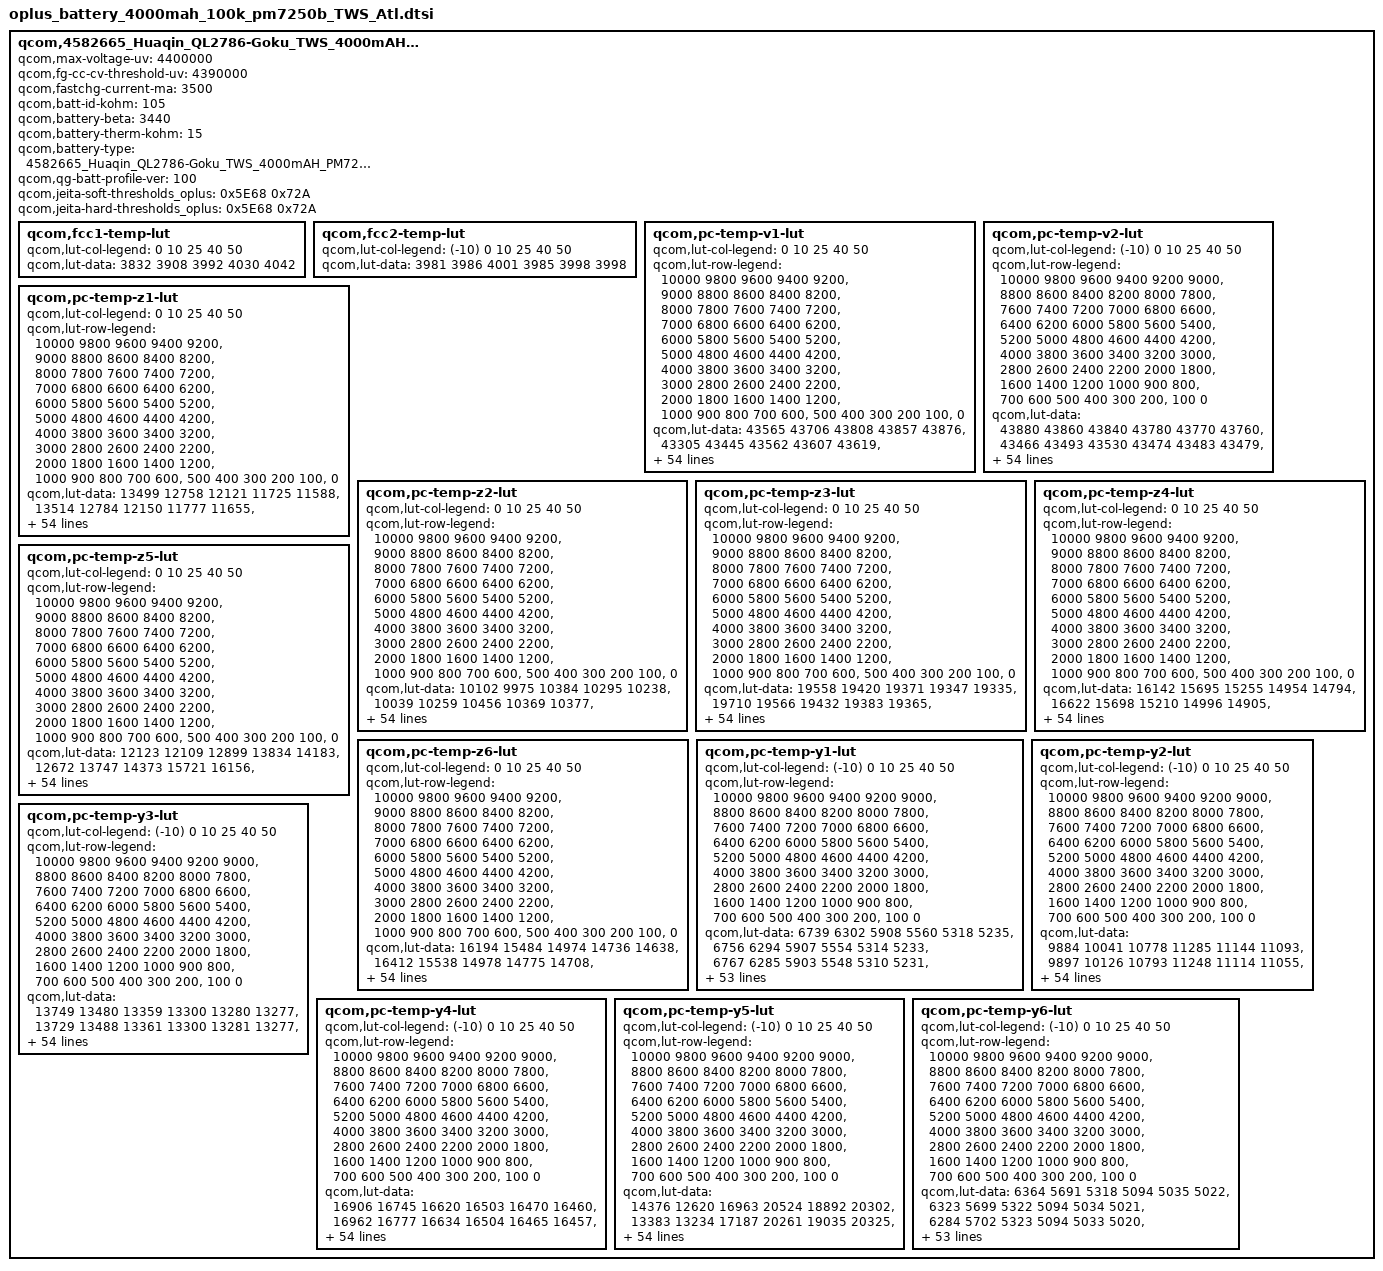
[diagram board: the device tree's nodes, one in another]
qcom,4582665_Huaqin_QL2786-Goku_TWS_4000mAH_PM7250B {
    /* 4582665_Huaqin_QL2786-Goku_TWS_4000mAH_PM7250B_averaged_MasterSlave_Dec05th2020 */
    qcom,max-voltage-uv = <4400000>;
    qcom,fg-cc-cv-threshold-uv = <4390000>;
    qcom,fastchg-current-ma = <3500>;
    qcom,batt-id-kohm = <105>;
    qcom,battery-beta = <3440>;
    qcom,battery-therm-kohm = <15>;
    qcom,battery-type = "4582665_Huaqin_QL2786-Goku_TWS_4000mAH_PM7250B_averaged_MasterSlave_Dec05th2020";
    qcom,qg-batt-profile-ver = <100>;
    qcom,jeita-soft-thresholds_oplus = <0x5E68 0x72A>;
    qcom,jeita-hard-thresholds_oplus = <0x5E68 0x72A>;

	qcom,fcc1-temp-lut {
		qcom,lut-col-legend = <0 10 25 40 50>;
		qcom,lut-data = <3832 3908 3992 4030 4042>;
	};

	qcom,fcc2-temp-lut {
		qcom,lut-col-legend = <(-10) 0 10 25 40 50>;
		qcom,lut-data = <3981 3986 4001 3985 3998 3998>;
	};

	qcom,pc-temp-v1-lut {
		qcom,lut-col-legend = <0 10 25 40 50>;
		qcom,lut-row-legend = <10000 9800 9600 9400 9200>,
			<9000 8800 8600 8400 8200>,
			<8000 7800 7600 7400 7200>,
			<7000 6800 6600 6400 6200>,
			<6000 5800 5600 5400 5200>,
			<5000 4800 4600 4400 4200>,
			<4000 3800 3600 3400 3200>,
			<3000 2800 2600 2400 2200>,
			<2000 1800 1600 1400 1200>,
			<1000 900 800 700 600>,
			<500 400 300 200 100>,
			<0>;
		qcom,lut-data = <43565 43706 43808 43857 43876>,
			<43305 43445 43562 43607 43619>,
			<43049 43194 43318 43370 43383>,
			<42801 42952 43076 43135 43151>,
			<42564 42714 42836 42900 42921>,
			<42335 42478 42597 42665 42691>,
			<42110 42246 42363 42432 42460>,
			<41889 42019 42130 42200 42227>,
			<41674 41796 41900 41969 41997>,
			<41467 41577 41672 41739 41766>,
			<41268 41365 41449 41511 41537>,
			<41068 41158 41232 41290 41316>,
			<40864 40956 41019 41074 41099>,
			<40660 40760 40813 40865 40890>,
			<40446 40565 40610 40660 40683>,
			<40218 40362 40416 40463 40484>,
			<40016 40158 40232 40276 40294>,
			<39867 39983 40057 40098 40114>,
			<39742 39842 39894 39927 39941>,
			<39615 39708 39745 39774 39784>,
			<39483 39562 39584 39612 39622>,
			<39352 39409 39395 39399 39419>,
			<39226 39238 39193 39148 39175>,
			<39102 39011 38990 38949 38974>,
			<38976 38785 38774 38800 38823>,
			<38837 38640 38616 38676 38696>,
			<38699 38535 38534 38572 38586>,
			<38583 38459 38472 38483 38490>,
			<38480 38406 38409 38399 38399>,
			<38399 38365 38346 38316 38309>,
			<38347 38325 38286 38241 38228>,
			<38308 38289 38229 38172 38156>,
			<38274 38253 38175 38110 38092>,
			<38244 38218 38126 38054 38032>,
			<38217 38184 38084 38006 37978>,
			<38189 38150 38043 37959 37926>,
			<38162 38118 38005 37911 37869>,
			<38126 38080 37965 37862 37810>,
			<38073 38019 37905 37798 37738>,
			<38000 37928 37812 37710 37647>,
			<37908 37825 37707 37608 37544>,
			<37779 37707 37597 37497 37431>,
			<37633 37570 37470 37370 37302>,
			<37466 37404 37305 37210 37142>,
			<37318 37255 37157 37067 37005>,
			<37221 37154 37058 36974 36917>,
			<37187 37126 37036 36948 36893>,
			<37160 37101 37015 36932 36875>,
			<37139 37076 36999 36913 36858>,
			<37088 37033 36953 36862 36800>,
			<36894 36833 36727 36614 36532>,
			<36449 36397 36292 36178 36096>,
			<35872 35829 35718 35603 35524>,
			<35091 35054 34934 34819 34744>,
			<33853 33843 33709 33604 33542>,
			<30000 30000 30000 30000 30000>;
	};

	qcom,pc-temp-v2-lut {
		qcom,lut-col-legend = <(-10) 0 10 25 40 50>;
		qcom,lut-row-legend = <10000 9800 9600 9400 9200 9000>,
			<8800 8600 8400 8200 8000 7800>,
			<7600 7400 7200 7000 6800 6600>,
			<6400 6200 6000 5800 5600 5400>,
			<5200 5000 4800 4600 4400 4200>,
			<4000 3800 3600 3400 3200 3000>,
			<2800 2600 2400 2200 2000 1800>,
			<1600 1400 1200 1000 900 800>,
			<700 600 500 400 300 200>,
			<100 0>;
		qcom,lut-data = <43880 43860 43840 43780 43770 43760>,
			<43466 43493 43530 43474 43483 43479>,
			<43095 43159 43238 43188 43211 43213>,
			<42774 42865 42967 42925 42957 42961>,
			<42493 42607 42717 42684 42719 42725>,
			<42241 42359 42472 42450 42486 42493>,
			<42025 42107 42227 42215 42252 42259>,
			<41823 41859 41986 41983 42019 42027>,
			<41588 41613 41753 41755 41790 41798>,
			<41304 41363 41525 41530 41564 41571>,
			<41066 41146 41305 41308 41341 41348>,
			<40936 40993 41093 41092 41122 41130>,
			<40827 40856 40888 40880 40907 40915>,
			<40617 40659 40688 40674 40702 40709>,
			<40183 40371 40491 40471 40501 40506>,
			<39783 40088 40295 40277 40309 40312>,
			<39559 39863 40102 40096 40124 40127>,
			<39383 39658 39906 39924 39946 39949>,
			<39207 39456 39697 39758 39776 39779>,
			<39032 39256 39471 39606 39618 39622>,
			<38867 39067 39254 39439 39446 39451>,
			<38706 38892 39056 39212 39227 39233>,
			<38555 38729 38874 38962 38994 39002>,
			<38431 38567 38714 38770 38808 38817>,
			<38328 38401 38572 38619 38651 38660>,
			<38240 38262 38447 38492 38517 38527>,
			<38166 38166 38339 38380 38405 38413>,
			<38103 38090 38240 38282 38307 38314>,
			<38043 38031 38142 38192 38218 38222>,
			<37986 37987 38041 38110 38136 38137>,
			<37932 37947 37960 38036 38062 38060>,
			<37880 37903 37899 37968 37996 37992>,
			<37829 37858 37849 37906 37934 37929>,
			<37774 37814 37809 37848 37868 37862>,
			<37716 37770 37778 37796 37801 37796>,
			<37656 37725 37744 37744 37729 37719>,
			<37593 37676 37706 37686 37644 37617>,
			<37526 37623 37664 37625 37553 37503>,
			<37458 37560 37609 37557 37468 37408>,
			<37385 37488 37538 37484 37389 37328>,
			<37314 37406 37453 37402 37305 37245>,
			<37246 37307 37351 37303 37213 37152>,
			<37180 37193 37230 37186 37109 37048>,
			<37114 37074 37084 37046 36970 36912>,
			<37043 36963 36945 36920 36853 36797>,
			<36953 36868 36844 36847 36802 36753>,
			<36896 36828 36812 36833 36787 36739>,
			<36838 36788 36777 36815 36775 36726>,
			<36767 36740 36729 36787 36747 36701>,
			<36657 36660 36645 36724 36675 36619>,
			<36453 36472 36451 36487 36383 36308>,
			<36087 36080 36024 36031 35902 35827>,
			<35521 35480 35418 35420 35276 35196>,
			<34685 34634 34576 34596 34414 34333>,
			<33254 33256 33244 33360 33133 33069>,
			<29010 28348 29127 28312 28764 29195>;
	};

	qcom,pc-temp-z1-lut {
		qcom,lut-col-legend = <0 10 25 40 50>;
		qcom,lut-row-legend = <10000 9800 9600 9400 9200>,
			<9000 8800 8600 8400 8200>,
			<8000 7800 7600 7400 7200>,
			<7000 6800 6600 6400 6200>,
			<6000 5800 5600 5400 5200>,
			<5000 4800 4600 4400 4200>,
			<4000 3800 3600 3400 3200>,
			<3000 2800 2600 2400 2200>,
			<2000 1800 1600 1400 1200>,
			<1000 900 800 700 600>,
			<500 400 300 200 100>,
			<0>;
		qcom,lut-data = <13499 12758 12121 11725 11588>,
			<13514 12784 12150 11777 11655>,
			<13530 12794 12165 11784 11666>,
			<13545 12798 12159 11783 11669>,
			<13539 12798 12145 11778 11667>,
			<13529 12790 12131 11773 11666>,
			<13525 12777 12117 11769 11665>,
			<13526 12759 12103 11765 11666>,
			<13523 12731 12093 11762 11666>,
			<13501 12710 12084 11760 11666>,
			<13451 12703 12079 11759 11665>,
			<13408 12698 12079 11758 11665>,
			<13382 12687 12079 11757 11665>,
			<13360 12658 12077 11757 11665>,
			<13335 12633 12073 11757 11665>,
			<13306 12627 12071 11757 11666>,
			<13285 12626 12073 11757 11666>,
			<13277 12627 12076 11758 11667>,
			<13273 12642 12077 11760 11668>,
			<13274 12657 12081 11761 11669>,
			<13279 12658 12084 11763 11670>,
			<13287 12656 12090 11764 11671>,
			<13305 12654 12096 11765 11671>,
			<13340 12654 12098 11767 11672>,
			<13363 12655 12100 11770 11674>,
			<13370 12660 12101 11773 11677>,
			<13375 12675 12104 11776 11680>,
			<13370 12686 12109 11781 11684>,
			<13334 12686 12113 11785 11688>,
			<13305 12684 12118 11789 11693>,
			<13312 12687 12123 11793 11697>,
			<13330 12691 12130 11798 11700>,
			<13344 12696 12138 11803 11703>,
			<13368 12706 12146 11808 11707>,
			<13391 12720 12156 11813 11711>,
			<13401 12728 12164 11817 11715>,
			<13417 12736 12167 11822 11718>,
			<13432 12743 12171 11827 11722>,
			<13445 12754 12175 11832 11725>,
			<13458 12768 12181 11838 11729>,
			<13465 12773 12188 11843 11732>,
			<13468 12774 12203 11849 11736>,
			<13468 12776 12217 11854 11740>,
			<13466 12809 12225 11859 11743>,
			<13490 12828 12234 11866 11746>,
			<13473 12803 12242 11870 11749>,
			<13475 12821 12242 11872 11749>,
			<13443 12819 12237 11872 11750>,
			<13471 12806 12258 11877 11754>,
			<13498 12822 12257 11881 11759>,
			<13491 12825 12258 11890 11764>,
			<13531 12848 12286 11901 11773>,
			<13524 12895 12299 11917 11785>,
			<13609 12944 12330 11937 11804>,
			<13609 12944 12330 11937 11804>,
			<13609 12944 12330 11937 11804>;
	};

	qcom,pc-temp-z2-lut {
		qcom,lut-col-legend = <0 10 25 40 50>;
		qcom,lut-row-legend = <10000 9800 9600 9400 9200>,
			<9000 8800 8600 8400 8200>,
			<8000 7800 7600 7400 7200>,
			<7000 6800 6600 6400 6200>,
			<6000 5800 5600 5400 5200>,
			<5000 4800 4600 4400 4200>,
			<4000 3800 3600 3400 3200>,
			<3000 2800 2600 2400 2200>,
			<2000 1800 1600 1400 1200>,
			<1000 900 800 700 600>,
			<500 400 300 200 100>,
			<0>;
		qcom,lut-data = <10102 9975 10384 10295 10238>,
			<10039 10259 10456 10369 10377>,
			<10108 10298 10494 10485 10499>,
			<10179 10278 10491 10538 10560>,
			<10231 10252 10453 10521 10526>,
			<10277 10220 10410 10491 10459>,
			<10288 10186 10369 10453 10409>,
			<10285 10170 10333 10395 10361>,
			<10279 10161 10322 10370 10333>,
			<10270 10155 10317 10376 10332>,
			<10252 10151 10315 10383 10335>,
			<10231 10148 10327 10379 10312>,
			<10203 10149 10349 10362 10240>,
			<10172 10166 10362 10338 10201>,
			<10141 10187 10373 10285 10216>,
			<10106 10200 10381 10239 10239>,
			<10087 10211 10389 10244 10249>,
			<10090 10226 10396 10272 10258>,
			<10096 10251 10405 10289 10269>,
			<10097 10278 10418 10295 10281>,
			<10091 10300 10438 10301 10299>,
			<10084 10321 10491 10392 10353>,
			<10085 10331 10552 10610 10469>,
			<10092 10334 10550 10677 10516>,
			<10102 10336 10496 10494 10444>,
			<10121 10337 10456 10319 10364>,
			<10145 10334 10446 10324 10374>,
			<10158 10333 10441 10367 10423>,
			<10166 10341 10450 10422 10458>,
			<10172 10356 10501 10517 10481>,
			<10178 10363 10536 10585 10495>,
			<10185 10366 10539 10564 10433>,
			<10191 10370 10539 10509 10276>,
			<10197 10377 10535 10481 10223>,
			<10203 10387 10527 10468 10237>,
			<10212 10393 10523 10462 10260>,
			<10223 10396 10531 10468 10298>,
			<10235 10400 10550 10483 10353>,
			<10250 10410 10574 10506 10402>,
			<10266 10427 10612 10556 10450>,
			<10283 10440 10638 10589 10482>,
			<10301 10449 10647 10571 10487>,
			<10323 10458 10650 10545 10483>,
			<10356 10466 10639 10539 10462>,
			<10602 10592 10681 10558 10458>,
			<10763 10646 10723 10555 10469>,
			<10809 10668 10692 10558 10479>,
			<10721 10734 10626 10555 10456>,
			<10399 10771 10636 10586 10507>,
			<10433 10790 10683 10668 10642>,
			<10705 10859 10833 10668 10440>,
			<12969 10853 10865 10479 10257>,
			<10137 10774 10818 10388 10218>,
			<10177 10615 10736 10345 10156>,
			<10177 10615 10736 10345 10156>,
			<10177 10615 10736 10345 10156>;
	};

	qcom,pc-temp-z3-lut {
		qcom,lut-col-legend = <0 10 25 40 50>;
		qcom,lut-row-legend = <10000 9800 9600 9400 9200>,
			<9000 8800 8600 8400 8200>,
			<8000 7800 7600 7400 7200>,
			<7000 6800 6600 6400 6200>,
			<6000 5800 5600 5400 5200>,
			<5000 4800 4600 4400 4200>,
			<4000 3800 3600 3400 3200>,
			<3000 2800 2600 2400 2200>,
			<2000 1800 1600 1400 1200>,
			<1000 900 800 700 600>,
			<500 400 300 200 100>,
			<0>;
		qcom,lut-data = <19558 19420 19371 19347 19335>,
			<19710 19566 19432 19383 19365>,
			<19804 19623 19474 19404 19385>,
			<19845 19653 19492 19415 19395>,
			<19821 19663 19503 19423 19398>,
			<19768 19662 19507 19428 19400>,
			<19731 19658 19503 19427 19401>,
			<19703 19653 19495 19424 19400>,
			<19685 19645 19489 19420 19400>,
			<19684 19636 19484 19415 19398>,
			<19685 19631 19478 19410 19394>,
			<19686 19626 19469 19403 19388>,
			<19687 19616 19460 19395 19379>,
			<19689 19591 19454 19388 19372>,
			<19697 19567 19450 19383 19369>,
			<19723 19559 19445 19379 19366>,
			<19741 19555 19437 19373 19362>,
			<19724 19548 19428 19366 19356>,
			<19690 19534 19422 19361 19351>,
			<19679 19522 19417 19358 19346>,
			<19681 19522 19415 19356 19343>,
			<19684 19527 19423 19361 19345>,
			<19686 19534 19437 19376 19354>,
			<19688 19545 19438 19380 19357>,
			<19692 19555 19432 19363 19341>,
			<19702 19556 19426 19346 19324>,
			<19714 19555 19418 19345 19325>,
			<19716 19553 19411 19344 19333>,
			<19713 19549 19411 19346 19344>,
			<19709 19545 19414 19364 19367>,
			<19703 19541 19419 19384 19385>,
			<19695 19537 19428 19390 19384>,
			<19686 19534 19438 19393 19378>,
			<19677 19533 19440 19393 19371>,
			<19667 19533 19437 19386 19363>,
			<19656 19532 19434 19377 19355>,
			<19643 19528 19428 19370 19350>,
			<19632 19523 19421 19365 19346>,
			<19622 19519 19417 19360 19342>,
			<19613 19515 19415 19357 19338>,
			<19606 19511 19413 19354 19336>,
			<19600 19505 19408 19353 19339>,
			<19593 19498 19403 19352 19344>,
			<19584 19488 19400 19352 19347>,
			<19520 19456 19390 19348 19344>,
			<19433 19441 19385 19343 19337>,
			<19383 19419 19376 19340 19328>,
			<19344 19404 19375 19333 19326>,
			<19263 19399 19352 19331 19313>,
			<19262 19400 19354 19324 19309>,
			<19262 19393 19337 19326 19340>,
			<19264 19377 19331 19343 19350>,
			<19305 19343 19331 19350 19350>,
			<19342 19339 19329 19350 19349>,
			<19342 19339 19329 19350 19349>,
			<19342 19339 19329 19350 19349>;
	};

	qcom,pc-temp-z4-lut {
		qcom,lut-col-legend = <0 10 25 40 50>;
		qcom,lut-row-legend = <10000 9800 9600 9400 9200>,
			<9000 8800 8600 8400 8200>,
			<8000 7800 7600 7400 7200>,
			<7000 6800 6600 6400 6200>,
			<6000 5800 5600 5400 5200>,
			<5000 4800 4600 4400 4200>,
			<4000 3800 3600 3400 3200>,
			<3000 2800 2600 2400 2200>,
			<2000 1800 1600 1400 1200>,
			<1000 900 800 700 600>,
			<500 400 300 200 100>,
			<0>;
		qcom,lut-data = <16142 15695 15255 14954 14794>,
			<16622 15698 15210 14996 14905>,
			<16368 15647 15155 14955 14885>,
			<16098 15444 15090 14911 14861>,
			<15922 15254 15007 14873 14836>,
			<15769 15144 14939 14837 14809>,
			<15640 15055 14893 14810 14786>,
			<15530 14987 14856 14787 14765>,
			<15434 14932 14822 14768 14748>,
			<15349 14888 14788 14750 14735>,
			<15273 14850 14766 14736 14725>,
			<15201 14819 14755 14728 14719>,
			<15127 14796 14747 14723 14715>,
			<15058 14778 14737 14717 14710>,
			<14996 14765 14726 14710 14703>,
			<14937 14759 14717 14702 14694>,
			<14893 14755 14711 14695 14687>,
			<14872 14750 14706 14689 14681>,
			<14857 14740 14700 14683 14675>,
			<14840 14730 14692 14674 14668>,
			<14818 14725 14688 14668 14663>,
			<14797 14721 14699 14687 14678>,
			<14784 14720 14725 14745 14736>,
			<14773 14775 14764 14790 14783>,
			<14768 14848 14837 14824 14813>,
			<14773 14863 14877 14844 14831>,
			<14782 14867 14868 14840 14826>,
			<14792 14868 14850 14824 14802>,
			<14807 14855 14832 14803 14773>,
			<14817 14830 14810 14769 14733>,
			<14814 14809 14788 14734 14699>,
			<14803 14792 14765 14713 14687>,
			<14792 14775 14743 14696 14680>,
			<14781 14760 14729 14689 14677>,
			<14771 14746 14720 14686 14675>,
			<14762 14734 14714 14685 14674>,
			<14755 14723 14710 14686 14676>,
			<14749 14717 14708 14689 14680>,
			<14743 14718 14710 14695 14686>,
			<14738 14722 14722 14708 14700>,
			<14737 14724 14729 14717 14710>,
			<14737 14719 14721 14712 14703>,
			<14735 14714 14711 14704 14693>,
			<14726 14713 14710 14706 14695>,
			<14717 14697 14696 14699 14690>,
			<14776 14686 14676 14682 14675>,
			<14825 14696 14670 14673 14673>,
			<14859 14701 14658 14660 14657>,
			<14942 14696 14664 14640 14645>,
			<14930 14689 14657 14642 14640>,
			<14928 14706 14700 14676 14650>,
			<14951 14742 14719 14667 14650>,
			<14931 14788 14721 14663 14652>,
			<14911 14803 14727 14666 14657>,
			<14911 14803 14727 14666 14657>,
			<14911 14803 14727 14666 14657>;
	};

	qcom,pc-temp-z5-lut {
		qcom,lut-col-legend = <0 10 25 40 50>;
		qcom,lut-row-legend = <10000 9800 9600 9400 9200>,
			<9000 8800 8600 8400 8200>,
			<8000 7800 7600 7400 7200>,
			<7000 6800 6600 6400 6200>,
			<6000 5800 5600 5400 5200>,
			<5000 4800 4600 4400 4200>,
			<4000 3800 3600 3400 3200>,
			<3000 2800 2600 2400 2200>,
			<2000 1800 1600 1400 1200>,
			<1000 900 800 700 600>,
			<500 400 300 200 100>,
			<0>;
		qcom,lut-data = <12123 12109 12899 13834 14183>,
			<12672 13747 14373 15721 16156>,
			<13361 14753 15590 16874 17841>,
			<13740 15430 16500 17686 18844>,
			<13724 16014 17236 18419 19178>,
			<13689 16562 17753 18977 19403>,
			<13684 17070 18043 19160 19743>,
			<13734 17608 18296 19254 20230>,
			<13820 18162 18839 19442 20814>,
			<13953 18828 19902 20258 21738>,
			<14183 20011 20658 21095 22620>,
			<14440 21390 20890 21051 22594>,
			<14703 21794 21076 20640 21877>,
			<15052 21808 21649 20475 21474>,
			<15809 21827 23032 21016 22284>,
			<17729 22198 23800 21651 23439>,
			<19058 23015 23716 21746 23785>,
			<18744 23412 23596 21692 23923>,
			<18072 23384 23748 21769 24148>,
			<17918 23364 24871 22638 24980>,
			<19059 24763 26772 24335 26411>,
			<20890 29763 34919 29547 28841>,
			<22699 35422 45175 39369 32753>,
			<24884 42954 45672 42122 34057>,
			<28001 49560 39076 31462 26327>,
			<36046 49552 32438 20352 17603>,
			<45068 45048 27496 18004 16422>,
			<46983 40528 23638 16797 16095>,
			<47028 37355 22688 16644 16194>,
			<47019 34729 22391 18304 19632>,
			<45479 33444 22291 20946 23939>,
			<41618 32648 24549 24663 26074>,
			<38383 32283 28820 29447 27624>,
			<36041 33303 32290 32060 28633>,
			<33888 35555 35764 33527 29443>,
			<31612 36906 37542 34233 29889>,
			<29184 37676 37378 33642 29642>,
			<27711 38126 36768 31985 28799>,
			<27116 38226 35926 29994 27438>,
			<26731 38281 34203 27041 24044>,
			<26604 38169 32139 24424 21566>,
			<26554 35491 29668 22924 21774>,
			<26758 32247 27455 21915 22181>,
			<28255 29502 26060 21338 22420>,
			<25663 27990 26650 21154 22215>,
			<16649 26271 27990 20913 20679>,
			<14175 20479 24754 20869 18433>,
			<13159 18241 25597 20229 19516>,
			<11402 17789 19277 23016 18754>,
			<11452 18384 20735 21322 18723>,
			<11512 17772 16007 16586 21527>,
			<11528 15206 14391 17621 21551>,
			<11885 13224 14117 18184 20184>,
			<12134 12819 13660 17262 18062>,
			<12134 12819 13660 17262 18062>,
			<12134 12819 13660 17262 18062>;
	};

	qcom,pc-temp-z6-lut {
		qcom,lut-col-legend = <0 10 25 40 50>;
		qcom,lut-row-legend = <10000 9800 9600 9400 9200>,
			<9000 8800 8600 8400 8200>,
			<8000 7800 7600 7400 7200>,
			<7000 6800 6600 6400 6200>,
			<6000 5800 5600 5400 5200>,
			<5000 4800 4600 4400 4200>,
			<4000 3800 3600 3400 3200>,
			<3000 2800 2600 2400 2200>,
			<2000 1800 1600 1400 1200>,
			<1000 900 800 700 600>,
			<500 400 300 200 100>,
			<0>;
		qcom,lut-data = <16194 15484 14974 14736 14638>,
			<16412 15538 14978 14775 14708>,
			<16299 15523 14976 14770 14711>,
			<16163 15427 14966 14763 14712>,
			<16039 15332 14930 14752 14706>,
			<15913 15268 14893 14737 14694>,
			<15810 15212 14868 14725 14684>,
			<15725 15166 14845 14713 14676>,
			<15654 15126 14824 14702 14668>,
			<15601 15093 14805 14692 14661>,
			<15559 15069 14790 14683 14654>,
			<15515 15048 14780 14675 14648>,
			<15460 15025 14772 14667 14641>,
			<15408 14995 14764 14661 14635>,
			<15374 14972 14756 14654 14630>,
			<15350 14964 14748 14649 14624>,
			<15330 14959 14741 14642 14619>,
			<15308 14954 14735 14636 14613>,
			<15289 14944 14729 14631 14607>,
			<15278 14936 14724 14625 14601>,
			<15272 14936 14721 14621 14597>,
			<15268 14938 14730 14634 14606>,
			<15268 14943 14749 14668 14638>,
			<15268 14973 14770 14686 14655>,
			<15269 15010 14798 14691 14659>,
			<15276 15019 14812 14693 14662>,
			<15288 15021 14807 14691 14660>,
			<15296 15022 14796 14685 14655>,
			<15302 15016 14788 14680 14650>,
			<15305 15005 14782 14675 14646>,
			<15304 14997 14777 14671 14641>,
			<15299 14989 14773 14666 14636>,
			<15294 14982 14770 14662 14631>,
			<15287 14978 14767 14658 14625>,
			<15280 14974 14763 14653 14620>,
			<15273 14970 14760 14649 14617>,
			<15267 14967 14756 14647 14615>,
			<15265 14965 14753 14645 14614>,
			<15266 14967 14753 14646 14615>,
			<15267 14972 14760 14650 14619>,
			<15270 14974 14764 14653 14622>,
			<15274 14975 14760 14651 14621>,
			<15277 14975 14756 14648 14620>,
			<15280 14975 14756 14650 14623>,
			<15255 14963 14750 14646 14620>,
			<15243 14954 14741 14636 14611>,
			<15238 14950 14734 14632 14605>,
			<15233 14944 14729 14623 14597>,
			<15229 14941 14721 14613 14585>,
			<15229 14943 14722 14611 14581>,
			<15239 14954 14735 14629 14603>,
			<15260 14970 14745 14637 14612>,
			<15288 14983 14752 14642 14616>,
			<15321 15005 14762 14648 14621>,
			<15321 15005 14762 14648 14621>,
			<15321 15005 14762 14648 14621>;
	};

	qcom,pc-temp-y1-lut {
		qcom,lut-col-legend = <(-10) 0 10 25 40 50>;
		qcom,lut-row-legend = <10000 9800 9600 9400 9200 9000>,
			<8800 8600 8400 8200 8000 7800>,
			<7600 7400 7200 7000 6800 6600>,
			<6400 6200 6000 5800 5600 5400>,
			<5200 5000 4800 4600 4400 4200>,
			<4000 3800 3600 3400 3200 3000>,
			<2800 2600 2400 2200 2000 1800>,
			<1600 1400 1200 1000 900 800>,
			<700 600 500 400 300 200>,
			<100 0>;
		qcom,lut-data = <6739 6302 5908 5560 5318 5235>,
			<6756 6294 5907 5554 5314 5233>,
			<6767 6285 5903 5548 5310 5231>,
			<6775 6276 5899 5541 5306 5228>,
			<6779 6269 5895 5535 5303 5225>,
			<6780 6266 5891 5529 5300 5224>,
			<6776 6268 5887 5523 5297 5223>,
			<6769 6270 5883 5518 5295 5223>,
			<6770 6269 5881 5513 5293 5223>,
			<6784 6262 5876 5508 5290 5222>,
			<6792 6258 5874 5505 5288 5222>,
			<6775 6258 5882 5505 5286 5221>,
			<6750 6259 5896 5505 5284 5221>,
			<6748 6258 5895 5504 5284 5220>,
			<6770 6256 5879 5500 5283 5220>,
			<6785 6255 5869 5497 5283 5220>,
			<6785 6264 5874 5498 5283 5219>,
			<6784 6279 5881 5500 5283 5220>,
			<6783 6280 5885 5501 5283 5220>,
			<6782 6268 5887 5502 5283 5220>,
			<6781 6258 5888 5503 5283 5220>,
			<6788 6260 5886 5504 5283 5221>,
			<6802 6264 5882 5506 5285 5221>,
			<6800 6268 5883 5508 5286 5222>,
			<6771 6279 5891 5512 5288 5224>,
			<6749 6287 5896 5516 5291 5226>,
			<6757 6282 5891 5522 5293 5227>,
			<6773 6272 5884 5528 5296 5228>,
			<6776 6268 5884 5531 5299 5230>,
			<6766 6258 5889 5533 5301 5233>,
			<6756 6252 5893 5535 5304 5235>,
			<6756 6250 5892 5539 5307 5238>,
			<6760 6247 5891 5546 5311 5241>,
			<6763 6246 5896 5552 5314 5243>,
			<6781 6253 5910 5557 5318 5245>,
			<6796 6259 5918 5561 5321 5246>,
			<6776 6265 5911 5566 5323 5249>,
			<6736 6274 5901 5572 5326 5251>,
			<6722 6276 5901 5575 5328 5253>,
			<6730 6270 5913 5576 5331 5254>,
			<6737 6263 5921 5578 5334 5255>,
			<6729 6248 5931 5584 5336 5257>,
			<6720 6232 5937 5594 5339 5259>,
			<6707 6244 5943 5611 5344 5262>,
			<6706 6254 5935 5627 5352 5267>,
			<6774 6279 5935 5632 5356 5270>,
			<6794 6287 5943 5635 5360 5272>,
			<6769 6271 5922 5642 5360 5272>,
			<6754 6276 5947 5644 5361 5273>,
			<6800 6282 5960 5652 5360 5275>,
			<6830 6288 5969 5653 5362 5277>,
			<6835 6316 5944 5659 5372 5283>,
			<6851 6313 5961 5694 5386 5292>,
			<6876 6338 5967 5713 5406 5305>,
			<6876 6338 5967 5713 5406 5305>,
			<6876 6338 5967 5713 5406 5305>;
	};

	qcom,pc-temp-y2-lut {
		qcom,lut-col-legend = <(-10) 0 10 25 40 50>;
		qcom,lut-row-legend = <10000 9800 9600 9400 9200 9000>,
			<8800 8600 8400 8200 8000 7800>,
			<7600 7400 7200 7000 6800 6600>,
			<6400 6200 6000 5800 5600 5400>,
			<5200 5000 4800 4600 4400 4200>,
			<4000 3800 3600 3400 3200 3000>,
			<2800 2600 2400 2200 2000 1800>,
			<1600 1400 1200 1000 900 800>,
			<700 600 500 400 300 200>,
			<100 0>;
		qcom,lut-data = <9884 10041 10778 11285 11144 11093>,
			<9897 10126 10793 11248 11114 11055>,
			<9928 10219 10802 11212 11080 11019>,
			<9974 10305 10807 11176 11043 10984>,
			<10031 10368 10808 11141 11007 10952>,
			<10099 10393 10807 11107 10975 10924>,
			<10179 10377 10800 11068 10937 10900>,
			<10271 10352 10789 11033 10904 10879>,
			<10374 10371 10789 11019 10905 10861>,
			<10506 10518 10799 11013 10942 10844>,
			<10578 10636 10813 11011 10970 10833>,
			<10577 10660 10832 11020 10970 10828>,
			<10575 10675 10858 11037 10964 10825>,
			<10548 10702 10899 11060 10977 10826>,
			<10371 10749 10968 11100 11024 10832>,
			<10235 10799 11030 11144 11078 10844>,
			<10065 10843 11077 11182 11122 10900>,
			<9778 10885 11111 11224 11169 11001>,
			<9702 10924 11110 11279 11234 11098>,
			<9694 10966 11078 11366 11334 11215>,
			<9688 10988 11057 11418 11387 11276>,
			<9684 10981 11076 11375 11354 11221>,
			<9680 10964 11110 11297 11292 11131>,
			<9678 10951 11130 11279 11246 11104>,
			<9676 10937 11145 11287 11204 11097>,
			<9675 10928 11159 11300 11183 11096>,
			<9674 10929 11176 11318 11194 11125>,
			<9673 10933 11189 11343 11216 11178>,
			<9672 10846 11190 11372 11244 11220>,
			<9670 10225 11180 11407 11307 11257>,
			<9669 9740 11172 11436 11372 11284>,
			<9667 9725 11169 11451 11433 11301>,
			<9666 9720 11166 11461 11485 11317>,
			<9666 9711 11159 11465 11495 11342>,
			<9665 9695 11139 11468 11497 11400>,
			<9664 9681 11114 11469 11498 11435>,
			<9663 9677 11087 11448 11457 11380>,
			<9662 9673 11054 11400 11388 11287>,
			<9662 9670 11012 11367 11358 11252>,
			<9661 9667 10955 11347 11337 11249>,
			<9661 9665 10888 11325 11327 11251>,
			<9661 9663 10819 11292 11360 11217>,
			<9660 9661 10724 11248 11393 11180>,
			<9660 9660 10468 11177 11299 11158>,
			<9659 9659 10019 11085 11165 11091>,
			<9658 9659 9871 11041 11056 10911>,
			<9658 9658 9793 11040 11033 10924>,
			<9658 9658 9737 11034 11149 10949>,
			<9657 9657 9713 11037 11144 11009>,
			<9657 9657 9700 11030 11162 11007>,
			<9657 9656 9691 10959 11061 10896>,
			<9656 9656 9675 10857 10950 10818>,
			<9655 9655 9666 10742 10901 10754>,
			<9652 9654 9660 10648 10852 10641>,
			<9652 9654 9660 10648 10852 10641>,
			<9652 9654 9660 10648 10852 10641>;
	};

	qcom,pc-temp-y3-lut {
		qcom,lut-col-legend = <(-10) 0 10 25 40 50>;
		qcom,lut-row-legend = <10000 9800 9600 9400 9200 9000>,
			<8800 8600 8400 8200 8000 7800>,
			<7600 7400 7200 7000 6800 6600>,
			<6400 6200 6000 5800 5600 5400>,
			<5200 5000 4800 4600 4400 4200>,
			<4000 3800 3600 3400 3200 3000>,
			<2800 2600 2400 2200 2000 1800>,
			<1600 1400 1200 1000 900 800>,
			<700 600 500 400 300 200>,
			<100 0>;
		qcom,lut-data = <13749 13480 13359 13300 13280 13277>,
			<13729 13488 13361 13300 13281 13277>,
			<13701 13492 13364 13301 13282 13278>,
			<13672 13494 13366 13302 13283 13279>,
			<13648 13495 13368 13304 13284 13279>,
			<13635 13495 13370 13305 13285 13280>,
			<13631 13491 13371 13306 13285 13281>,
			<13629 13485 13373 13308 13286 13282>,
			<13613 13482 13373 13309 13287 13283>,
			<13546 13481 13372 13310 13288 13284>,
			<13497 13480 13371 13311 13289 13285>,
			<13493 13459 13370 13311 13290 13286>,
			<13491 13428 13368 13311 13290 13287>,
			<13485 13421 13366 13311 13291 13287>,
			<13473 13426 13361 13310 13294 13288>,
			<13462 13429 13358 13309 13296 13288>,
			<13454 13422 13358 13308 13297 13289>,
			<13448 13408 13357 13306 13298 13292>,
			<13445 13397 13355 13306 13297 13292>,
			<13444 13387 13348 13309 13295 13292>,
			<13442 13379 13341 13311 13291 13291>,
			<13437 13371 13337 13308 13289 13287>,
			<13428 13364 13333 13302 13286 13281>,
			<13417 13358 13330 13298 13284 13280>,
			<13400 13353 13328 13296 13282 13279>,
			<13388 13348 13326 13294 13281 13279>,
			<13393 13344 13324 13293 13280 13279>,
			<13406 13339 13323 13293 13279 13279>,
			<13422 13329 13322 13293 13279 13278>,
			<13444 13303 13319 13293 13280 13276>,
			<13469 13285 13317 13294 13280 13275>,
			<13492 13309 13317 13294 13281 13275>,
			<13515 13358 13317 13294 13282 13276>,
			<13539 13375 13317 13294 13283 13277>,
			<13564 13377 13320 13295 13282 13279>,
			<13591 13379 13324 13295 13282 13280>,
			<13623 13392 13326 13295 13281 13278>,
			<13658 13417 13328 13294 13281 13277>,
			<13691 13443 13329 13294 13280 13276>,
			<13721 13473 13331 13295 13279 13277>,
			<13752 13507 13333 13295 13279 13278>,
			<13786 13545 13337 13296 13281 13279>,
			<13824 13588 13340 13296 13283 13280>,
			<13875 13632 13340 13297 13280 13278>,
			<13933 13681 13347 13298 13280 13277>,
			<13935 13685 13347 13298 13284 13283>,
			<13946 13710 13363 13302 13286 13284>,
			<14012 13755 13382 13306 13292 13288>,
			<14078 13801 13406 13313 13295 13291>,
			<14143 13840 13428 13319 13297 13290>,
			<14215 13879 13451 13315 13289 13286>,
			<14305 13937 13466 13315 13288 13286>,
			<14516 14035 13526 13324 13295 13289>,
			<15084 14194 13662 13336 13300 13295>,
			<15084 14194 13662 13336 13300 13295>,
			<15084 14194 13662 13336 13300 13295>;
	};

	qcom,pc-temp-y4-lut {
		qcom,lut-col-legend = <(-10) 0 10 25 40 50>;
		qcom,lut-row-legend = <10000 9800 9600 9400 9200 9000>,
			<8800 8600 8400 8200 8000 7800>,
			<7600 7400 7200 7000 6800 6600>,
			<6400 6200 6000 5800 5600 5400>,
			<5200 5000 4800 4600 4400 4200>,
			<4000 3800 3600 3400 3200 3000>,
			<2800 2600 2400 2200 2000 1800>,
			<1600 1400 1200 1000 900 800>,
			<700 600 500 400 300 200>,
			<100 0>;
		qcom,lut-data = <16906 16745 16620 16503 16470 16460>,
			<16962 16777 16634 16504 16465 16457>,
			<17008 16818 16656 16505 16461 16454>,
			<17043 16862 16679 16506 16460 16453>,
			<17066 16898 16697 16507 16459 16451>,
			<17074 16918 16705 16507 16459 16451>,
			<17061 16926 16703 16508 16460 16451>,
			<17040 16930 16701 16510 16463 16452>,
			<17044 16928 16701 16512 16466 16453>,
			<17100 16909 16706 16516 16469 16456>,
			<17165 16897 16714 16522 16472 16459>,
			<17222 16981 16729 16529 16477 16462>,
			<17272 17121 16751 16539 16484 16467>,
			<17246 17131 16773 16551 16490 16472>,
			<17016 16998 16801 16567 16494 16479>,
			<16846 16882 16816 16586 16500 16486>,
			<16854 16848 16806 16610 16510 16492>,
			<16874 16825 16783 16635 16524 16499>,
			<16872 16796 16754 16649 16545 16511>,
			<16843 16763 16708 16659 16578 16537>,
			<16810 16729 16663 16664 16596 16551>,
			<16779 16699 16624 16620 16566 16533>,
			<16752 16670 16591 16538 16512 16500>,
			<16747 16634 16572 16503 16484 16478>,
			<16755 16580 16558 16489 16466 16460>,
			<16762 16549 16550 16483 16458 16452>,
			<16763 16551 16546 16485 16461 16453>,
			<16764 16557 16543 16489 16468 16457>,
			<16763 16573 16535 16493 16475 16464>,
			<16757 16637 16517 16500 16485 16475>,
			<16751 16684 16506 16506 16495 16488>,
			<16749 16673 16508 16513 16506 16499>,
			<16749 16651 16512 16519 16516 16509>,
			<16749 16647 16519 16522 16517 16511>,
			<16749 16663 16532 16523 16516 16511>,
			<16749 16680 16547 16523 16514 16511>,
			<16749 16689 16565 16519 16500 16496>,
			<16749 16695 16583 16511 16479 16472>,
			<16749 16700 16594 16508 16475 16468>,
			<16754 16703 16602 16507 16475 16468>,
			<16763 16706 16606 16506 16475 16469>,
			<16778 16699 16602 16509 16476 16472>,
			<16799 16686 16596 16513 16478 16473>,
			<16825 16675 16590 16511 16468 16460>,
			<16841 16672 16600 16508 16458 16450>,
			<16804 16666 16600 16504 16460 16452>,
			<16790 16671 16618 16512 16472 16470>,
			<16804 16690 16648 16529 16488 16495>,
			<16820 16719 16687 16551 16517 16525>,
			<16831 16771 16732 16578 16537 16537>,
			<16824 16777 16754 16551 16480 16466>,
			<16797 16733 16737 16539 16469 16458>,
			<16814 16710 16739 16553 16476 16460>,
			<16975 16725 16771 16589 16499 16479>,
			<16975 16725 16771 16589 16499 16479>,
			<16975 16725 16771 16589 16499 16479>;
	};

	qcom,pc-temp-y5-lut {
		qcom,lut-col-legend = <(-10) 0 10 25 40 50>;
		qcom,lut-row-legend = <10000 9800 9600 9400 9200 9000>,
			<8800 8600 8400 8200 8000 7800>,
			<7600 7400 7200 7000 6800 6600>,
			<6400 6200 6000 5800 5600 5400>,
			<5200 5000 4800 4600 4400 4200>,
			<4000 3800 3600 3400 3200 3000>,
			<2800 2600 2400 2200 2000 1800>,
			<1600 1400 1200 1000 900 800>,
			<700 600 500 400 300 200>,
			<100 0>;
		qcom,lut-data = <14376 12620 16963 20524 18892 20302>,
			<13383 13234 17187 20261 19035 20325>,
			<13155 14245 17481 19920 19048 20301>,
			<13528 15350 17778 19553 18956 20239>,
			<14340 16243 18009 19213 18781 20145>,
			<15430 16618 18109 18953 18545 20024>,
			<17425 16557 18101 18635 18042 19748>,
			<19609 16452 18064 18200 17360 19315>,
			<19528 16411 17982 17797 16912 18888>,
			<16517 16398 17724 17271 16614 18379>,
			<14409 16430 17360 16710 16287 17853>,
			<16832 16619 16627 16107 15706 17354>,
			<20958 17045 15820 15473 15135 16841>,
			<21543 18083 15909 14977 15095 16244>,
			<19181 21222 17309 14523 15411 15484>,
			<17188 23302 19026 14298 15616 15094>,
			<16134 22852 21073 14447 15416 15206>,
			<14836 22060 22990 14881 15103 15400>,
			<14574 21924 23385 16005 15070 15450>,
			<14637 22251 23335 19914 15269 15316>,
			<14673 22633 23277 23045 15631 15270>,
			<14401 22983 23384 23790 18332 16830>,
			<13793 23304 23540 24234 22172 19386>,
			<13251 23129 23448 24067 22674 20464>,
			<12639 21324 23026 22321 21259 21008>,
			<12270 19507 22765 20684 19672 21227>,
			<12252 17945 23403 20049 18195 20287>,
			<12247 15805 24357 19603 16940 18470>,
			<12272 14321 24250 19548 16731 17038>,
			<12487 12971 22725 19845 16758 15665>,
			<12760 12233 21249 20267 16811 15003>,
			<13026 12701 20267 20728 17411 15192>,
			<13311 13634 19543 21286 18420 15654>,
			<13449 13975 19567 21861 18959 16463>,
			<13553 14012 20238 22577 19263 18223>,
			<13618 14019 20753 23010 19529 19263>,
			<13621 14223 20765 22629 19860 19069>,
			<13622 14581 20652 21695 20137 18716>,
			<13598 14695 20585 20936 19914 18492>,
			<13333 14745 20327 20199 18485 18277>,
			<13044 14770 20168 19480 17550 18155>,
			<12895 14673 20371 18738 18348 18644>,
			<12792 14485 20553 18146 19162 19154>,
			<12915 14139 18644 18041 18356 19366>,
			<13251 13947 15974 17955 18271 18071>,
			<13556 13627 14379 17349 17813 18992>,
			<13546 13803 14600 17589 16757 17119>,
			<13812 13939 14492 17270 18526 17345>,
			<14138 14271 14736 17657 17940 16868>,
			<14319 14208 15243 18144 17955 16518>,
			<14283 14231 15675 18022 17636 17831>,
			<13836 14132 14591 18563 18032 18500>,
			<13058 13704 14187 19668 21447 20000>,
			<11859 13398 13932 20872 24085 24762>,
			<11859 13398 13932 20872 24085 24762>,
			<11859 13398 13932 20872 24085 24762>;
	};

	qcom,pc-temp-y6-lut {
		qcom,lut-col-legend = <(-10) 0 10 25 40 50>;
		qcom,lut-row-legend = <10000 9800 9600 9400 9200 9000>,
			<8800 8600 8400 8200 8000 7800>,
			<7600 7400 7200 7000 6800 6600>,
			<6400 6200 6000 5800 5600 5400>,
			<5200 5000 4800 4600 4400 4200>,
			<4000 3800 3600 3400 3200 3000>,
			<2800 2600 2400 2200 2000 1800>,
			<1600 1400 1200 1000 900 800>,
			<700 600 500 400 300 200>,
			<100 0>;
		qcom,lut-data = <6364 5691 5318 5094 5035 5022>,
			<6323 5699 5322 5094 5034 5021>,
			<6284 5702 5323 5094 5033 5020>,
			<6247 5701 5322 5094 5033 5020>,
			<6215 5697 5321 5094 5034 5021>,
			<6187 5691 5318 5094 5034 5021>,
			<6166 5682 5314 5094 5035 5022>,
			<6147 5670 5309 5095 5036 5023>,
			<6119 5658 5304 5096 5037 5024>,
			<6077 5643 5300 5097 5039 5026>,
			<6053 5635 5298 5098 5041 5027>,
			<6058 5643 5299 5100 5042 5029>,
			<6066 5657 5300 5103 5044 5031>,
			<6056 5655 5301 5106 5047 5032>,
			<5979 5626 5304 5109 5050 5034>,
			<5915 5596 5306 5113 5053 5037>,
			<5902 5580 5303 5119 5057 5039>,
			<5894 5567 5297 5125 5061 5043>,
			<5887 5554 5287 5130 5066 5047>,
			<5882 5542 5269 5134 5072 5053>,
			<5877 5531 5251 5136 5076 5057>,
			<5870 5522 5237 5122 5066 5049>,
			<5863 5514 5226 5094 5048 5035>,
			<5861 5507 5220 5082 5038 5027>,
			<5864 5498 5216 5077 5032 5021>,
			<5869 5494 5214 5074 5029 5019>,
			<5878 5497 5214 5075 5029 5020>,
			<5892 5507 5215 5077 5031 5021>,
			<5908 5519 5215 5079 5033 5022>,
			<5928 5537 5212 5081 5037 5025>,
			<5950 5558 5211 5084 5040 5028>,
			<5971 5580 5214 5087 5045 5031>,
			<5993 5604 5222 5090 5048 5035>,
			<6017 5632 5231 5093 5049 5037>,
			<6040 5663 5244 5095 5049 5038>,
			<6065 5698 5259 5096 5049 5039>,
			<6094 5734 5277 5096 5044 5034>,
			<6125 5772 5297 5095 5038 5026>,
			<6155 5812 5318 5095 5037 5024>,
			<6182 5854 5339 5097 5037 5025>,
			<6211 5898 5363 5099 5037 5026>,
			<6246 5941 5392 5103 5039 5028>,
			<6285 5984 5422 5108 5041 5030>,
			<6334 6026 5454 5113 5037 5024>,
			<6389 6075 5497 5118 5036 5022>,
			<6399 6089 5502 5120 5039 5027>,
			<6413 6115 5536 5127 5045 5033>,
			<6469 6157 5576 5137 5054 5044>,
			<6528 6205 5621 5152 5064 5054>,
			<6589 6255 5670 5166 5071 5058>,
			<6654 6295 5712 5159 5050 5034>,
			<6727 6338 5748 5165 5047 5033>,
			<6932 6417 5859 5194 5056 5037>,
			<7526 6569 6027 5236 5069 5049>,
			<7526 6569 6027 5236 5069 5049>,
			<7526 6569 6027 5236 5069 5049>;
	};

};
